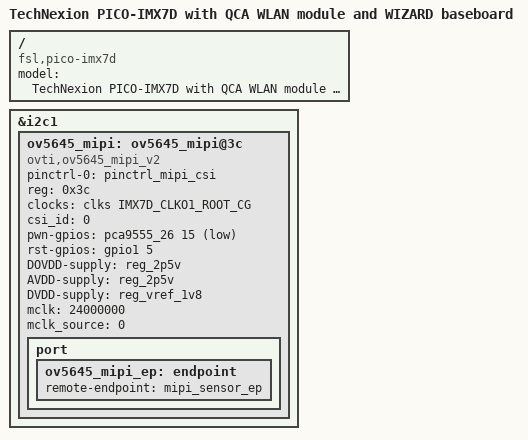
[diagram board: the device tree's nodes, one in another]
/*
 * Copyright 2018 Technexion Ltd.
 *
 * Author: Tapani Utriainen <tapani@technexion.com>
 *	   Richard Hu <richard.hu@technexion.com>
 *
 * This program is free software; you can redistribute it and/or modify
 * it under the terms of the GNU General Public License version 2 as
 * published by the Free Software Foundation.
 *
 */
/dts-v1/;

#include "imx7d.dtsi"
#include "imx7d-pico-qca.dtsi"
#include "imx7d-baseboard_pico_wizard.dtsi"

/delete-node/ &ov5645_mipi;

/ {
	model = "TechNexion PICO-IMX7D with QCA WLAN module and WIZARD baseboard";
	compatible = "fsl,pico-imx7d", "fsl,imx7d";

	/delete-node/ sound;
};

&i2c1 {
    ov5645_mipi: ov5645_mipi@3c {
        compatible = "ovti,ov5645_mipi_v2";
        pinctrl-names = "default";
        pinctrl-0 = <&pinctrl_mipi_csi>; /* GPIO_P69:mipi clock, GPIO_P65:reset */
        reg = <0x3c>;
        clocks = <&clks IMX7D_CLKO1_ROOT_CG>;
        clock-names = "csi_mclk";
        csi_id = <0>;
        pwn-gpios = <&pca9555_26 15 1>;
        rst-gpios = <&gpio1 5 0>;
        DOVDD-supply = <&reg_2p5v>;
        AVDD-supply = <&reg_2p5v>;
        DVDD-supply = <&reg_vref_1v8>;
        mclk = <24000000>;
        mclk_source = <0>;
        port {
            ov5645_mipi_ep: endpoint {
                remote-endpoint = <&mipi_sensor_ep>;
            };
        };
    };
};
